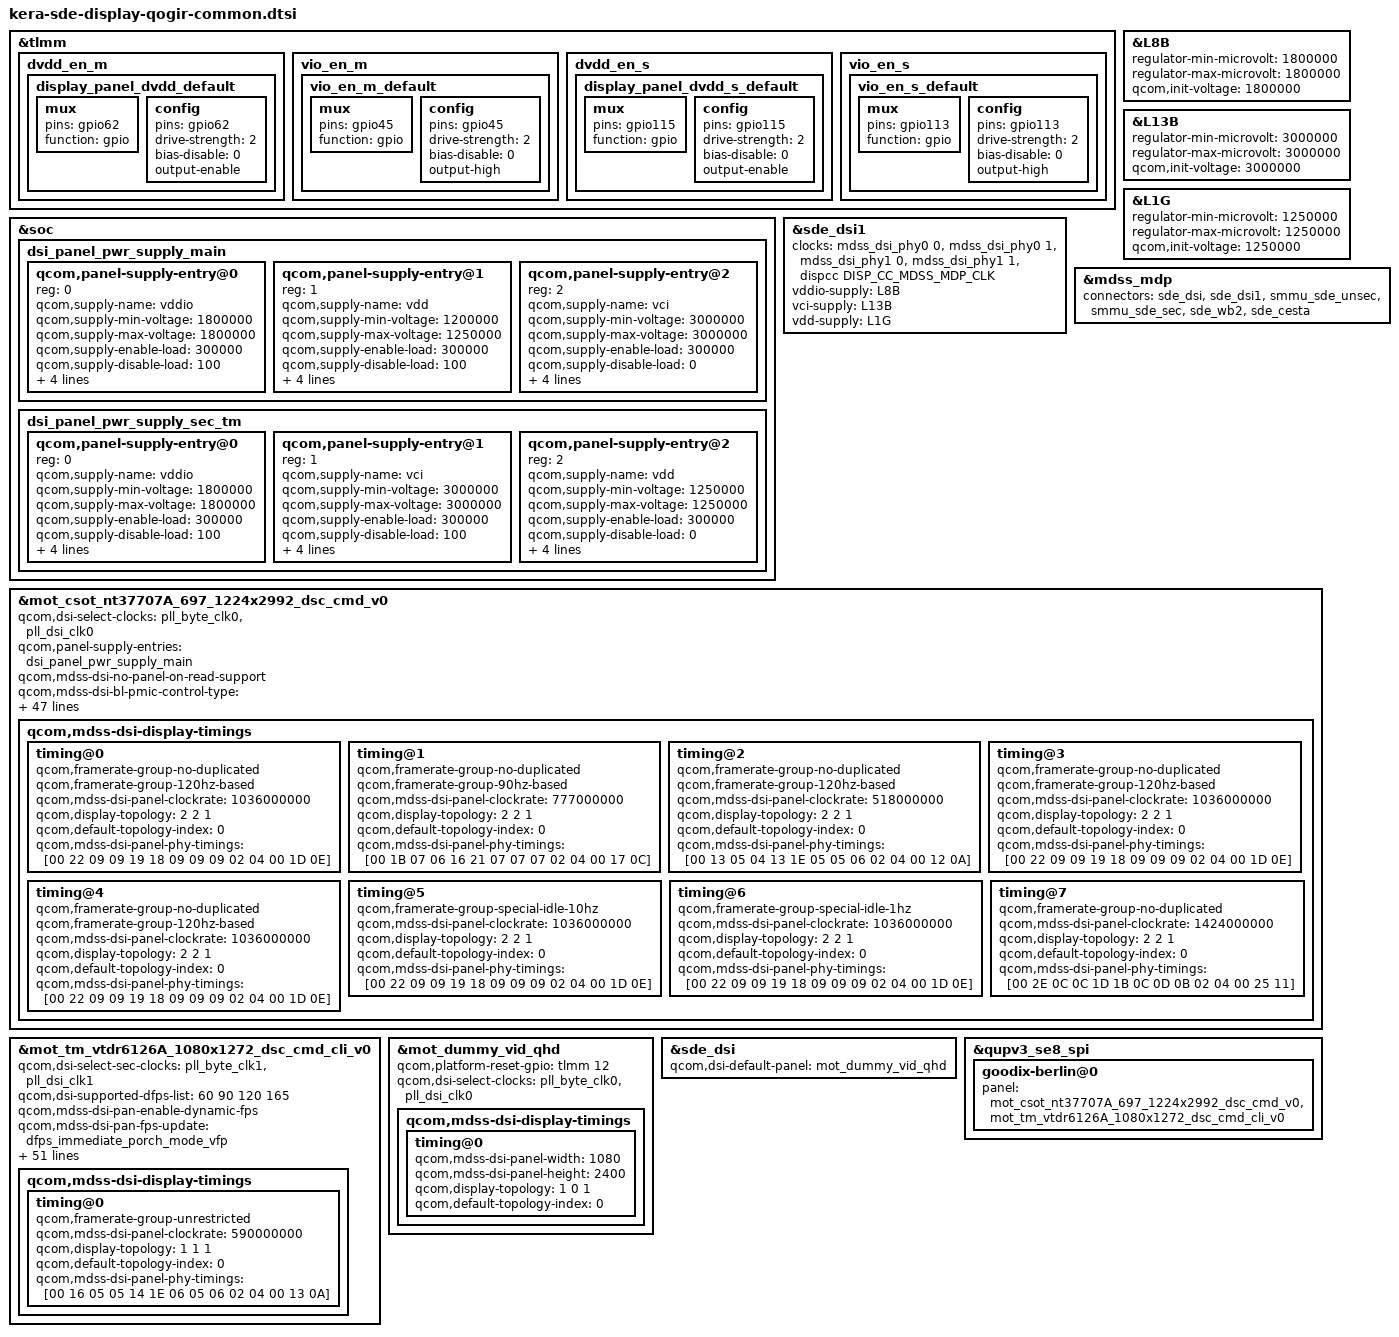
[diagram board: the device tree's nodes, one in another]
// SPDX-License-Identifier: BSD-3-Clause
/*
 * Copyright (c) 2023-2024, Qualcomm Innovation Center, Inc. All rights reserved.
 */

#include "kera-sde.dtsi"
#include "kera-sde-display.dtsi"
#include "dsi-panel-mot-dummy-qhd-video.dtsi"
#include "dsi-panel-mot-csot-nt37707A-697-1224x2992-dsc-cmd-common_falcon_v0.dtsi"
#include "dsi-panel-mot-tm-vtdr6126A-1080x1272-dsc-vid-common-cli_falcon_v0.dtsi"

&tlmm {
	dvdd_en_m {
		display_panel_dvdd_default: display_panel_dvdd_default { //dvdd 1.23V
			mux {
				pins = "gpio62";
				function = "gpio";
			};

			config {
				pins = "gpio62";
				drive-strength = <2>;   /* 2 mA */
				bias-disable = <0>;   /* no pull */
				output-enable;
			};
		};
	};
	vio_en_m {
		vio_en_m_default: vio_en_m_default {//vio enable 1.8V
			mux {
				pins = "gpio45";
				function = "gpio";
			};

			config {
				pins = "gpio45";
				drive-strength = <2>;   /* 2 mA */
				bias-disable = <0>;   /* no pull */
				output-high;
			};
		};
	};
	dvdd_en_s {
		display_panel_dvdd_s_default: display_panel_dvdd_s_default {
			mux {
				pins = "gpio115";
				function = "gpio";
			};

			config {
				pins = "gpio115";
				drive-strength = <2>;   /* 2 mA */
				bias-disable = <0>;   /* no pull */
				output-enable;
			};
		};
	};
	vio_en_s {
		vio_en_s_default: vio_en_s_default {
			mux {
				pins = "gpio113";
				function = "gpio";
			};

			config {
				pins = "gpio113";
				drive-strength = <2>;   /* 2 mA */
				bias-disable = <0>;   /* no pull */
				output-high;
			};
		};
	};
};

&soc {
	dsi_panel_pwr_supply_main: dsi_panel_pwr_supply_main {
		#address-cells = <1>;
		#size-cells = <0>;

	qcom,panel-supply-entry@0 {
		reg = <0>;
		qcom,supply-name = "vddio";
		qcom,supply-min-voltage = <1800000>;
		qcom,supply-max-voltage = <1800000>;
		qcom,supply-enable-load = <300000>;
		qcom,supply-disable-load = <100>;
		qcom,supply-pre-on-sleep = <0>;
		qcom,supply-post-on-sleep = <1>;
		qcom,supply-pre-off-sleep = <0>;
		qcom,supply-post-off-sleep = <0>;
        };
	qcom,panel-supply-entry@1 {
		reg = <1>;
		qcom,supply-name = "vdd";
		qcom,supply-min-voltage = <1200000>;
		qcom,supply-max-voltage = <1250000>;
		qcom,supply-enable-load = <300000>;
		qcom,supply-disable-load = <100>;
		qcom,supply-pre-on-sleep = <0>;
		qcom,supply-post-on-sleep = <1>;
		qcom,supply-pre-off-sleep = <0>;
		qcom,supply-post-off-sleep = <1>;
        };

        qcom,panel-supply-entry@2 {
		reg = <2>;
		qcom,supply-name = "vci";
		qcom,supply-min-voltage = <3000000>;
		qcom,supply-max-voltage = <3000000>;
		qcom,supply-enable-load = <300000>;
		qcom,supply-disable-load = <0>;
		qcom,supply-pre-on-sleep = <0>;
		qcom,supply-post-on-sleep = <0>;
		qcom,supply-pre-off-sleep = <0>;
		qcom,supply-post-off-sleep = <1>;
        };
	};
	dsi_panel_pwr_supply_sec_tm: dsi_panel_pwr_supply_sec_tm {
		#address-cells = <1>;
		#size-cells = <0>;

	qcom,panel-supply-entry@0 {
		reg = <0>;
		qcom,supply-name = "vddio";
		qcom,supply-min-voltage = <1800000>;
		qcom,supply-max-voltage = <1800000>;
		qcom,supply-enable-load = <300000>;
		qcom,supply-disable-load = <100>;
		qcom,supply-pre-on-sleep = <0>;
		qcom,supply-post-on-sleep = <1>;
		qcom,supply-pre-off-sleep = <0>;
		qcom,supply-post-off-sleep = <0>;
        };
	qcom,panel-supply-entry@1 {
		reg = <1>;
		qcom,supply-name = "vci";
		qcom,supply-min-voltage = <3000000>;
		qcom,supply-max-voltage = <3000000>;
		qcom,supply-enable-load = <300000>;
		qcom,supply-disable-load = <100>;
		qcom,supply-pre-on-sleep = <0>;
		qcom,supply-post-on-sleep = <1>;
		qcom,supply-pre-off-sleep = <0>;
		qcom,supply-post-off-sleep = <1>;
        };

        qcom,panel-supply-entry@2 {
		reg = <2>;
		qcom,supply-name = "vdd";
		qcom,supply-min-voltage = <1250000>;
		qcom,supply-max-voltage = <1250000>;
		qcom,supply-enable-load = <300000>;
		qcom,supply-disable-load = <0>;
		qcom,supply-pre-on-sleep = <0>;
		qcom,supply-post-on-sleep = <0>;
		qcom,supply-pre-off-sleep = <0>;
		qcom,supply-post-off-sleep = <1>;
        };
	};
};

&L8B {
       regulator-min-microvolt = <1800000>;
       regulator-max-microvolt = <1800000>;
       qcom,init-voltage = <1800000>;
};

&L13B {
       regulator-min-microvolt = <3000000>;
       regulator-max-microvolt = <3000000>;
       qcom,init-voltage = <3000000>;
};

&L1G {
       regulator-min-microvolt = <1250000>;
       regulator-max-microvolt = <1250000>;
       qcom,init-voltage = <1250000>;
};

&sde_dsi1 {
	clocks = <&mdss_dsi_phy0 0>,
		 <&mdss_dsi_phy0 1>,
		 <&mdss_dsi_phy1 0>,
		 <&mdss_dsi_phy1 1>,
		 <&dispcc DISP_CC_MDSS_MDP_CLK>;
	clock-names = "pll_byte_clk0", "pll_dsi_clk0",
		      "pll_byte_clk1", "pll_dsi_clk1",
		      "mdp_core_clk";

	vddio-supply = <&L8B>;
	vci-supply = <&L13B>;
	vdd-supply = <&L1G>;
};

&mdss_mdp {
	connectors = <&sde_dsi &sde_dsi1 &smmu_sde_unsec &smmu_sde_sec &sde_wb2 &sde_cesta>;
};

&mot_csot_nt37707A_697_1224x2992_dsc_cmd_v0 {
	qcom,dsi-select-clocks = "pll_byte_clk0", "pll_dsi_clk0";
	qcom,panel-supply-entries = <&dsi_panel_pwr_supply_main>;
	qcom,mdss-dsi-no-panel-on-read-support;
	qcom,mdss-dsi-bl-pmic-control-type = "bl_ctrl_dcs";
	qcom,mdss-dsi-bl-min-level = <420>;
	qcom,mdss-dsi-bl-max-level = <15584>;
	qcom,mdss-dsi-bl-default-level = <8190>;
	qcom,mdss-brightness-max-level = <15584>;
	qcom,platform-reset-gpio = <&tlmm 12 0>;
	qcom,platform-vdd-enable-gpio = <&tlmm 62 0>;
	qcom,platform-vio-enable-gpio = <&tlmm 45 0>;
	qcom,bl-dsc-cmd-state = "dsi_hs_mode";
	qcom,mdss-dsi-bl-inverted-dbv;
	qcom,mdss-dsi-bl-is-exponent;

	qcom,mdss-dsi-panel-status-check-mode = "reg_read";
	qcom,mdss-dsi-panel-status-command = [06 01 00 01 00 00 01 0a];
	qcom,mdss-dsi-panel-status-command-state = "dsi_lp_mode";
	qcom,mdss-dsi-panel-status-value = <0x9c>;
	qcom,mdss-dsi-panel-status-read-length = <1>;
	qcom,esd-check-enabled;
	qcom,cellid-read-enabled;
	qcom,mdss-dsi-panel-cellid-read-length = <36>;
	qcom,mdss-dsi-panel-cellid-offset = <13>;
	qcom,mdss-dsi-panel-cellid-command = [
		06 01 00 01 00 00 01 AC];

	qcom,mdss-dsi-panel-hdr-enabled;
	qcom,mdss-dsi-panel-hdr-color-primaries = <15600 16450 34000
	        16000 13250 34500 7500 3000>;
	qcom,mdss-dsi-panel-peak-brightness = <20000000>;
	qcom,mdss-dsi-panel-blackness-level = <1>;

	qcom,apl-enabled;
	qcom,mdss-dsi-panel-APL-THRESHOLD-BL = <12000>;
	qcom,mdss-dsi-panel-APL-FUNC-ID = <0>;
	qcom,mdss-dsi-panel-apl-on-command = [
		39 00 00 00 00 00 03 5F 00 01];
	qcom,mdss-dsi-panel-apl-off-command = [
		39 00 00 00 00 00 03 5F 00 00];
	qcom,partition-refreshrate-enabled;
	qcom,mdss-dsi-panel-boundaryLine-reg-count = <6>;
	//qcom,ulps-enabled;
	qcom,mdss-dsi-hbm-off-command = [
		39 00 00 40 00 00 03 5F 00 00
		39 00 00 00 00 00 03 51 2C 50
	];
	qcom,mdss-dsi-hbm-off-command-state = "dsi_hs_mode";
	qcom,mdss-dsi-hbm-on-command = [
		39 00 00 40 00 00 03 5F 00 01
		39 00 00 00 00 00 03 51 3F FC
	];
	qcom,mdss-dsi-hbm-on-command-state = "dsi_hs_mode";
	qcom,mdss-dsi-display-timings {
		timing@0 { //120
			qcom,framerate-group-no-duplicated;
			qcom,framerate-group-120hz-based;
			qcom,mdss-dsi-panel-clockrate = <1036000000>;
			qcom,display-topology = <2 2 1>;
			qcom,default-topology-index = <0>;
			qcom,mdss-dsi-panel-phy-timings = [00 22 09 09 19 18 09
							09 09 02 04 00 1D 0E];
		};
		timing@1 { //90
			qcom,framerate-group-no-duplicated;
			qcom,framerate-group-90hz-based;
			qcom,mdss-dsi-panel-clockrate = <777000000>;
			qcom,display-topology = <2 2 1>;
			qcom,default-topology-index = <0>;
			qcom,mdss-dsi-panel-phy-timings = [00 1B 07 06 16 21 07
							07 07 02 04 00 17 0C];
		};
		timing@2 { //60
			qcom,framerate-group-no-duplicated;
			qcom,framerate-group-120hz-based;
			qcom,mdss-dsi-panel-clockrate = <518000000>;
			qcom,display-topology = <2 2 1>;
			qcom,default-topology-index = <0>;
			qcom,mdss-dsi-panel-phy-timings = [00 13 05 04 13 1E 05
							05 06 02 04 00 12 0A];
		};
		timing@3 { //30
			qcom,framerate-group-no-duplicated;
			qcom,framerate-group-120hz-based;
			qcom,mdss-dsi-panel-clockrate = <1036000000>;
			qcom,display-topology = <2 2 1>;
			qcom,default-topology-index = <0>;
			qcom,mdss-dsi-panel-phy-timings = [00 22 09 09 19 18 09
							09 09 02 04 00 1D 0E];
		};
		timing@4 { //24
			qcom,framerate-group-no-duplicated;
			qcom,framerate-group-120hz-based;
			qcom,mdss-dsi-panel-clockrate = <1036000000>;
			qcom,display-topology = <2 2 1>;
			qcom,default-topology-index = <0>;
			qcom,mdss-dsi-panel-phy-timings = [00 22 09 09 19 18 09
							09 09 02 04 00 1D 0E];
		};
		timing@5 { //10 independent
			qcom,framerate-group-special-idle-10hz;
			qcom,mdss-dsi-panel-clockrate = <1036000000>;
			qcom,display-topology = <2 2 1>;
			qcom,default-topology-index = <0>;
			qcom,mdss-dsi-panel-phy-timings = [00 22 09 09 19 18 09
							09 09 02 04 00 1D 0E];
		};
		timing@6 { //1 independent
			qcom,framerate-group-special-idle-1hz;
			qcom,mdss-dsi-panel-clockrate = <1036000000>;
			qcom,display-topology = <2 2 1>;
			qcom,default-topology-index = <0>;
			qcom,mdss-dsi-panel-phy-timings = [00 22 09 09 19 18 09
							09 09 02 04 00 1D 0E];
		};
		timing@7 { //165
			qcom,framerate-group-no-duplicated;
			qcom,mdss-dsi-panel-clockrate = <1424000000>;
			qcom,display-topology = <2 2 1>;
			qcom,default-topology-index = <0>;
			qcom,mdss-dsi-panel-phy-timings = [00 2E 0C 0C 1D 1B 0C
							0D 0B 02 04 00 25 11];
		};
	};
};

&mot_tm_vtdr6126A_1080x1272_dsc_cmd_cli_v0 {
	qcom,dsi-select-sec-clocks = "pll_byte_clk1", "pll_dsi_clk1";

	qcom,dsi-supported-dfps-list = <60 90 120 165>;
	qcom,mdss-dsi-pan-enable-dynamic-fps;
	qcom,mdss-dsi-pan-fps-update = "dfps_immediate_porch_mode_vfp";
	qcom,mdss-dsi-pan-dfps-send-command;

	qcom,panel-supply-entries = <&dsi_panel_pwr_supply_main>;
	qcom,panel-sec-supply-entries = <&dsi_panel_pwr_supply_sec_tm>;
	qcom,mdss-dsi-bl-pmic-control-type = "bl_ctrl_dcs";
	qcom,mdss-dsi-sec-bl-pmic-control-type = "bl_ctrl_dcs";
	qcom,mdss-dsi-bl-min-level = <420>;
	qcom,mdss-dsi-bl-max-level = <16380>;
	qcom,mdss-dsi-bl-default-level = <10230>;
	qcom,mdss-brightness-max-level = <16380>;
	qcom,platform-sec-reset-gpio = <&tlmm 110 0>;
	qcom,platform-sec-vdd-enable-gpio = <&tlmm 115 0>;
	qcom,platform-sec-vio-enable-gpio = <&tlmm 113 0>;
	qcom,mdss-dsi-panel-orientation = "180";
	qcom,mdss-dsi-panel-status-check-mode = "reg_read";
	qcom,mdss-dsi-panel-status-command = [06 01 00 01 00 00 01 0A];
	qcom,mdss-dsi-panel-status-command-state = "dsi_hs_mode";
	qcom,mdss-dsi-panel-status-value = <0x9C>;
	qcom,mdss-dsi-panel-status-read-length = <1>;
	qcom,esd-check-enabled;
	qcom,mdss-dsi-bl-inverted-dbv;
	qcom,mdss-dsi-bl-is-exponent;

	qcom,mdss-dsi-no-panel-on-read-support;
	qcom,cellid-read-enabled;
	qcom,mdss-dsi-panel-cellid-read-length = <23>;
	qcom,mdss-dsi-panel-cellid-command = [
		06 01 00 01 00 00 01 5A];

	qcom,mdss-dsi-panel-hdr-enabled;
	qcom,mdss-dsi-panel-hdr-color-primaries = <15600 16450 34000
	        16000 13250 34500 7500 3000>;
	qcom,mdss-dsi-panel-peak-brightness = <15000000>;
	qcom,mdss-dsi-panel-blackness-level = <1>;

	//DIC OTP enable&threshold default, no need config,
	//here is only for aura25 tianma cli panel record.
	qcom,apl-enabled;
	qcom,mdss-dsi-panel-APL-THRESHOLD-BL = <16100>;

	qcom,mdss-dsi-panel-AOD-config-enabled;
	//qcom,mdss-dsi-panel-AOD-THRESHOLD-BL = <5292>;
	qcom,mdss-dsi-panel-AOD-bl-vid-update;

	qcom,mdss-dsi-panel-AOD-THRESHOLD-min-nit = <1312>;
	qcom,mdss-dsi-panel-AOD-THRESHOLD-hig-nit = <5292>;

	qcom,mdss-dsi-panel-AOD-bl-min = <0>; //5nit
	qcom,mdss-dsi-panel-AOD-bl-mid = <1>; //60nit
	qcom,mdss-dsi-panel-AOD-bl-hig = <2>; //160nit
	qcom,mdss-dsi-panel-sf-brightnesszone-enable = <0>;

	qcom,mdss-dsi-display-timings {
		timing@0{
			qcom,framerate-group-unrestricted;
			qcom,mdss-dsi-panel-clockrate = <590000000>;
			qcom,display-topology = <1 1 1>;
			qcom,default-topology-index = <0>;
			qcom,mdss-dsi-panel-phy-timings = [00 16 05 05 14 1E 06
							05 06 02 04 00 13 0A];
		};
	};
};

&mot_dummy_vid_qhd {
	qcom,mdss-dsi-display-timings {
		timing@0{
			qcom,mdss-dsi-panel-width = <1080>;
			qcom,mdss-dsi-panel-height = <2400>;
		};
	};
};

&mot_dummy_vid_qhd {
	qcom,platform-reset-gpio = <&tlmm 12 0>;

	qcom,dsi-select-clocks = "pll_byte_clk0", "pll_dsi_clk0";
	qcom,mdss-dsi-display-timings {
		timing@0 {
			qcom,display-topology = <1 0 1>;
			qcom,default-topology-index = <0>;
		};
	};
};

&sde_dsi {
	qcom,dsi-default-panel = <&mot_dummy_vid_qhd>;
};


&qupv3_se8_spi {
	goodix-berlin@0 {
		panel = <&mot_csot_nt37707A_697_1224x2992_dsc_cmd_v0
                        &mot_tm_vtdr6126A_1080x1272_dsc_cmd_cli_v0>;
	};
};
